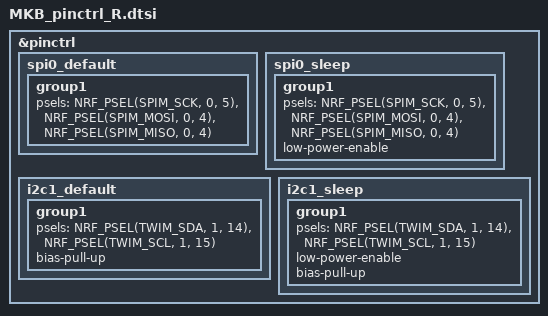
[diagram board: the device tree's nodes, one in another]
#include <zephyr/dt-bindings/input/input-event-codes.h>
// #define INPUT_EV_KEY 0x01               /**< Key event */
// #define INPUT_EV_REL 0x02               /**< Relative coordinate event */
// #define INPUT_EV_ABS 0x03               /**< Absolute coordinate event */
// #define INPUT_EV_MSC 0x04               /**< Miscellaneous event */
// #define INPUT_EV_VENDOR_START 0xf0      /**< Vendor specific event start */
// #define INPUT_EV_VENDOR_STOP 0xff       /**< Vendor specific event stop */
// #define INPUT_REL_X 0x00                /**< Relative X coordinate */
// #define INPUT_REL_Y 0x01                /**< Relative Y coordinate */
// #define INPUT_REL_WHEEL 0x08            /**< Relative wheel coordinate */
// #define INPUT_REL_HWHEEL 0x06           /**< Relative horizontal wheel coordinate */
// #define INPUT_REL_MISC 0x09             /**< Relative misc coordinate */

&pinctrl {
    spi0_default: spi0_default {
        group1 {
            psels = <NRF_PSEL(SPIM_SCK, 0, 5)>,
                    <NRF_PSEL(SPIM_MOSI, 0, 4)>,
                    <NRF_PSEL(SPIM_MISO, 0, 4)>;
        };
    };

    spi0_sleep: spi0_sleep {
        group1 {
            psels = <NRF_PSEL(SPIM_SCK, 0, 5)>,
                    <NRF_PSEL(SPIM_MOSI, 0, 4)>,
                    <NRF_PSEL(SPIM_MISO, 0, 4)>;
            low-power-enable;
        };
    };

    i2c1_default: i2c1_default {
        group1 {
            psels = <NRF_PSEL(TWIM_SDA, 1, 14)>,
                    <NRF_PSEL(TWIM_SCL, 1, 15)>;
            bias-pull-up;
        };
    };
      
    i2c1_sleep: i2c1_sleep {
        group1 {
            psels = <NRF_PSEL(TWIM_SDA, 1, 14)>,
                    <NRF_PSEL(TWIM_SCL, 1, 15)>;
            low-power-enable;
            bias-pull-up;
        };
    };
};
